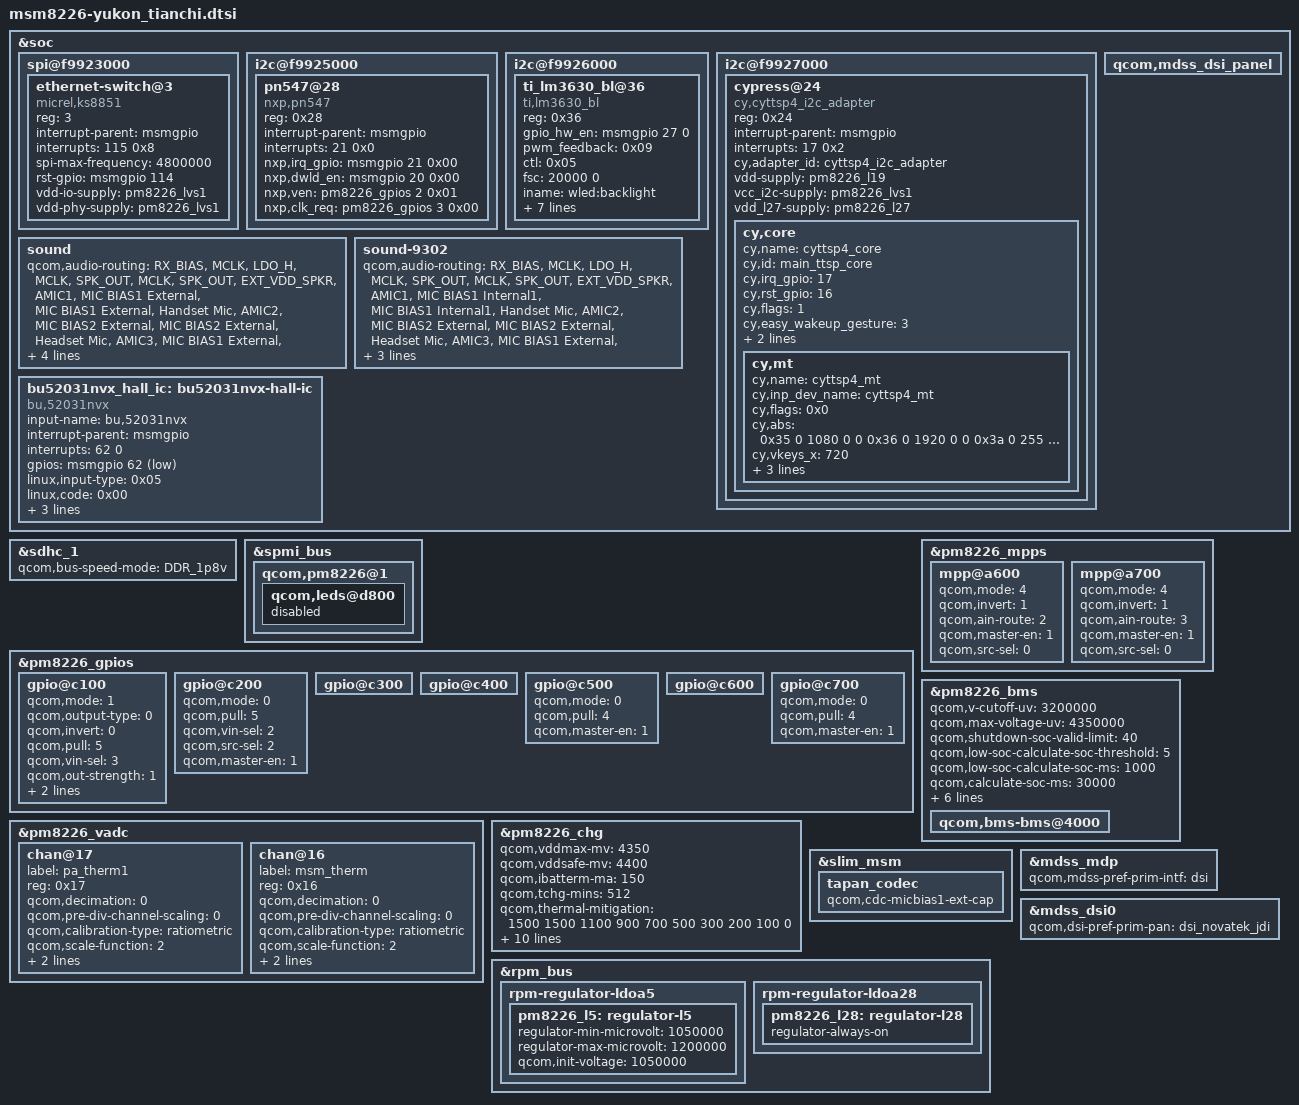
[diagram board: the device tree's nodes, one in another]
/* Copyright (c) 2013, The Linux Foundation. All rights reserved.
 * Copyright (C) 2014 Sony Mobile Communications AB.
 *
 * This program is free software; you can redistribute it and/or modify
 * it under the terms of the GNU General Public License version 2 and
 * only version 2 as published by the Free Software Foundation.
 *
 * This program is distributed in the hope that it will be useful,
 * but WITHOUT ANY WARRANTY; without even the implied warranty of
 * MERCHANTABILITY or FITNESS FOR A PARTICULAR PURPOSE.  See the
 * GNU General Public License for more details.
 *
 * NOTE: This file has been modified by Sony Mobile Communications AB.
 * Modifications are licensed under the License.
 */

/include/ "msm8226-yukon_common.dtsi"
/include/ "dsi-panel-tianchi.dtsi"
/include/ "msm8226-yukon_tianchi-camera-sensor.dtsi"

&soc {

	spi@f9923000 {
		ethernet-switch@3 {
			compatible = "micrel,ks8851";
			reg = <3>;
			interrupt-parent = <&msmgpio>;
			interrupts = <115 0x8>;
			spi-max-frequency = <4800000>;
			rst-gpio = <&msmgpio 114 0>;
			vdd-io-supply = <&pm8226_lvs1>;
			vdd-phy-supply = <&pm8226_lvs1>;
		};
	};

	i2c@f9925000 { /* BLSP-1 QUP-3 */
		pn547@28 {
			compatible = "nxp,pn547";
			reg = <0x28>;
			interrupt-parent = <&msmgpio>;
			interrupts = <21 0x0>;
			nxp,irq_gpio = <&msmgpio 21 0x00>;
			nxp,dwld_en = <&msmgpio 20 0x00>;
			nxp,ven = <&pm8226_gpios 2 0x01>;
			nxp,clk_req = <&pm8226_gpios 3 0x00>;
		};
	};

	i2c@f9926000 { /* BLSP-1 QUP-4 */
		ti_lm3630_bl@36 {
			compatible = "ti,lm3630_bl";
			reg = <0x36>;
			gpio_hw_en = <&msmgpio 27 0>;
			pwm_feedback = <0x09>;
			ctl = <0x05>;
			fsc = <20000 0>;
			iname = "wled:backlight";
			connected = <0x01 0x00>;
			bank = <0x00 0x01>;
			filter_str = <0x03>;
			ovp_boost = <0x46>;
			led_fault = <0x00>;
			intf_name = "wled:backlight";
			brightness = <255 0>;
		};
	};

	i2c@f9927000 { /* BLSP1 QUP5 */
		cypress@24 {
			compatible = "cy,cyttsp4_i2c_adapter";
			reg = <0x24>;
			interrupt-parent = <&msmgpio>;
			interrupts = <17 0x2>;
			cy,adapter_id = "cyttsp4_i2c_adapter";
			vdd-supply = <&pm8226_l19>;
			vcc_i2c-supply = <&pm8226_lvs1>;
			vdd_l27-supply = <&pm8226_l27>;

			cy,core {
				cy,name = "cyttsp4_core";
				cy,id = "main_ttsp_core";

				cy,irq_gpio = <17>;
				cy,rst_gpio = <16>;

				/* Enable cy,max_xfer_len to limit max I2C/SPI transfer length */
				/* cy,max_xfer_len = <0x100>; */

				/* CY_CORE_FLAG_WAKE_ON_GESTURE */
				cy,flags = <1>;
				/* CY_CORE_EWG_TAP_TAP | CY_CORE_EWG_TWO_FINGER_SLIDE */
				cy,easy_wakeup_gesture = <3>;
				cy,btn_keys = <102 /* KEY_HOME */
						139 /* KEY_MENU */
						158 /* KEY_BACK */
						217 /* KEY_SEARCH */
						114 /* KEY_VOLUMEDOWN */
						115 /* KEY_VOLUMEUP */
						212 /* KEY_CAMERA */
						116>; /* KEY_POWER */
				cy,btn_keys-tag = <0>;

				cy,mt {
					cy,name = "cyttsp4_mt";
					cy,inp_dev_name = "cyttsp4_mt";
					/* CY_MT_FLAG_FLIP | CY_MT_FLAG_INV_X | CY_MT_FLAG_INV_Y */
					cy,flags = <0x0>;
					cy,abs =
						/* ABS_MT_POSITION_X, CY_ABS_MIN_X, CY_ABS_MAX_X, 0, 0 */
						<0x35 0 1080 0 0
						/* ABS_MT_POSITION_Y, CY_ABS_MIN_Y, CY_ABS_MAX_Y, 0, 0 */
						0x36 0 1920 0 0
						/* ABS_MT_PRESSURE, CY_ABS_MIN_P, CY_ABS_MAX_P, 0, 0 */
						0x3a 0 255 0 0
						/* CY_IGNORE_VALUE, CY_ABS_MIN_W, CY_ABS_MAX_W, 0, 0 */
						0xffff 0 255 0 0
						/* ABS_MT_TRACKING_ID, CY_ABS_MIN_T, CY_ABS_MAX_T, 0, 0 */
						0x39 0 15 0 0
						/* ABS_MT_TOUCH_MAJOR, 0, 255, 0, 0 */
						0x30 0 255 0 0
						/* ABS_MT_TOUCH_MINOR, 0, 255, 0, 0 */
						0x31 0 255 0 0
						/* ABS_MT_ORIENTATION, -128, 127, 0, 0 */
						0x34 0xfffffed7 127 0 0>;

					cy,vkeys_x = <720>;
					cy,vkeys_y = <1280>;

					cy,virtual_keys = /* KeyCode CenterX CenterY Width Height */
						/* KEY_BACK */
						<158 1360 90 160 180
						/* KEY_MENU */
						139 1360 270 160 180
						/* KEY_HOME */
						102 1360 450 160 180
						/* KEY SEARCH */
						217 1360 630 160 180>;
				};
			};
		};
	};

	sound {
		qcom,audio-routing =
			"RX_BIAS", "MCLK",
			"LDO_H", "MCLK",
			"SPK_OUT", "MCLK",
			"SPK_OUT", "EXT_VDD_SPKR",
			"AMIC1", "MIC BIAS1 External",
			"MIC BIAS1 External", "Handset Mic",
			"AMIC2", "MIC BIAS2 External",
			"MIC BIAS2 External", "Headset Mic",
			"AMIC3", "MIC BIAS1 External",
			"MIC BIAS1 External", "Secondary Mic";

		qcom,cdc-mclk-gpios = <&pm8226_gpios 1 0>;
		#qcom,cdc-vdd-spkr-gpios = <&pm8226_gpios 2 0>;
		qcom,headset-jack-type-NC;
	};

	sound-9302 {
		qcom,audio-routing =
			"RX_BIAS", "MCLK",
			"LDO_H", "MCLK",
			"SPK_OUT", "MCLK",
			"SPK_OUT", "EXT_VDD_SPKR",
			"AMIC1", "MIC BIAS1 Internal1",
			"MIC BIAS1 Internal1", "Handset Mic",
			"AMIC2", "MIC BIAS2 External",
			"MIC BIAS2 External", "Headset Mic",
			"AMIC3", "MIC BIAS1 External",
			"MIC BIAS1 External", "Handset Mic";

		qcom,cdc-mclk-gpios = <&pm8226_gpios 1 0>;
		qcom,cdc-vdd-spkr-gpios = <&pm8226_gpios 2 0>;
	};

	bu52031nvx_hall_ic: bu52031nvx-hall-ic {
		compatible = "bu,52031nvx";
		input-name = "bu,52031nvx";
		interrupt-parent = <&msmgpio>;
		interrupts = <62 0>;
		gpios = <&msmgpio 62 0x1>;
		linux,input-type = <0x05>;
		linux,code = <0x00>;
		gpio-key,wakeup;
		detection_delay = <50>;
		detection_cycles = <4>;
	};

        qcom,mdss_dsi_panel {
                status = "ok";
        };

};

&sdhc_1 {
	qcom,bus-speed-mode = "DDR_1p8v";
};

&spmi_bus {
	qcom,pm8226@1 {
		qcom,leds@d800 {
			status = "disabled";
		};
	};
};

&pm8226_gpios {
	/* GPIO_2: NFC_EN*/
	gpio@c100 {
		qcom,mode = <1>; /* QPNP_PIN_MODE_DIG_OUT */
		qcom,output-type = <0>; /* QPNP_PIN_OUT_BUF_CMOS */
		qcom,invert = <0>; /* QPNP_PIN_INVERT_DISABLE */
		qcom,pull = <5>; /* QPNP_PIN_PULL_NO */
		qcom,vin-sel = <3>; /* QPNP_PIN_VIN3 = VREG_L6 */
		qcom,out-strength = <1>; /* QPNP_PIN_OUT_STRENGTH_LOW */
		qcom,src-sel = <0>; /* QPNP_PIN_SEL_FUNC_CONSTANT */
		qcom,master-en = <1>; /* enable this gpio */
	};

	/* GPIO_3: NFC_CLK_REQ*/
	gpio@c200 {
		qcom,mode = <0>;		/* QPNP_PIN_MODE_DIG_IN */
		qcom,pull = <5>;		/* QPNP_PIN_PULL_NO */
		qcom,vin-sel = <2>;		/* QPNP_PIN_VIN2 */
		qcom,src-sel = <2>;		/* QPNP_PIN_SEL_FUNC_1 */
		qcom,master-en = <1>;
	};

	/* GPIO_4: BATT_UIM_ALARM*/
	/* Follow QCT */
	gpio@c300 {
	};

	/* GPIO_5: FLASH_STROBE_TRIG*/
	/* Follow QCT */
	gpio@c400 {
	};

	/* GPIO_6: NC*/
	gpio@c500 {
		qcom,mode = <0>;		/* QPNP_PIN_MODE_DIG_IN */
		qcom,pull = <4>;		/* QPNP_PIN_PULL_DN */
		qcom,master-en = <1>;
	};

	/* GPIO_7: TX_GTR_THRESH*/
	/* Follow QCT */
	gpio@c600 {
	};

	/* GPIO_8: NC*/
	gpio@c700 {
		qcom,mode = <0>;		/* QPNP_PIN_MODE_DIG_IN */
		qcom,pull = <4>;		/* QPNP_PIN_PULL_DN */
		qcom,master-en = <1>;
	};
};

&pm8226_mpps {
	mpp@a600 {
		/* MSM_THERM config */
		qcom,mode = <4>; /* AIN input */
		qcom,invert = <1>; /* Enable MPP */
		qcom,ain-route = <2>; /* AMUX 7 */
		qcom,master-en = <1>;
		qcom,src-sel = <0>; /* Function constant */
	};

	mpp@a700 {
		/* PA_THERM1 config */
		qcom,mode = <4>; /* AIN input */
		qcom,invert = <1>; /* Enable MPP */
		qcom,ain-route = <3>; /* AMUX 8 */
		qcom,master-en = <1>;
		qcom,src-sel = <0>; /* Function constant */
	};
};

&pm8226_vadc {
	chan@17 {
		label = "pa_therm1";
		reg = <0x17>;
		qcom,decimation = <0>;
		qcom,pre-div-channel-scaling = <0>;
		qcom,calibration-type = "ratiometric";
		qcom,scale-function = <2>;
		qcom,hw-settle-time = <2>;
		qcom,fast-avg-setup = <0>;
	};

	chan@16 {
		label = "msm_therm";
		reg = <0x16>;
		qcom,decimation = <0>;
		qcom,pre-div-channel-scaling = <0>;
		qcom,calibration-type = "ratiometric";
		qcom,scale-function = <2>;
		qcom,hw-settle-time = <2>;
		qcom,fast-avg-setup = <0>;
	};
};

&pm8226_bms {
	status = "ok";

	qcom,v-cutoff-uv = <3200000>;
	qcom,max-voltage-uv = <4350000>;
	qcom,shutdown-soc-valid-limit = <40>;
	qcom,low-soc-calculate-soc-threshold = <5>;
	qcom,low-soc-calculate-soc-ms = <1000>;
	qcom,calculate-soc-ms = <30000>;
	qcom,batt-type = <3>;
	qcom,use-external-rsense;
	qcom,ocv-voltage-high-threshold-uv = <3800000>;
	qcom,ocv-voltage-low-threshold-uv = <3750000>;
	qcom,clamp-soc-max-count = <2>;
	qcom,chg-term-ua = <150000>;

	qcom,bms-bms@4000 {
		status = "ok";
	};
};

&pm8226_chg {
	qcom,vddmax-mv = <4350>;
	qcom,vddsafe-mv = <4400>;
	qcom,ibatterm-ma = <150>;
	qcom,tchg-mins = <512>;
	qcom,thermal-mitigation = <1500 1500 1100 900 700 500 300 200 100 0>;
	qcom,ibatmax-cool-ma = <900>;
	qcom,cool-bat-decidegc = <100>;
	qcom,cool-bat-mv = <4350>;
	qcom,ibatmax-warm-ma = <900>;
	qcom,warm-bat-decidegc = <450>;
	qcom,warm-bat-mv = <4200>;
	qcom,vbatdet-delta-mv = <20>;
	qcom,vbatdet-delta-soc = <1>;
	qcom,ibatmax-cool-ma = <900>;
	qcom,batt-hot-percentage = <25>;
	qcom,duty-cycle-100p;
};

&slim_msm {
	tapan_codec {
		qcom,cdc-micbias1-ext-cap;
	};
};

&rpm_bus {
	rpm-regulator-ldoa5 {
		pm8226_l5: regulator-l5 {
			regulator-min-microvolt = <1050000>;
		        regulator-max-microvolt = <1200000>;
			qcom,init-voltage = <1050000>;
		};
	};
	rpm-regulator-ldoa28 {
		pm8226_l28: regulator-l28 {
			regulator-always-on;
		};
	};
};

&bu52031nvx_hall_ic {
        status = "ok";
};

&mdss_mdp {
        qcom,mdss-pref-prim-intf = "dsi";
};


&mdss_dsi0 {
	qcom,dsi-pref-prim-pan = <&dsi_novatek_jdi>;
};
